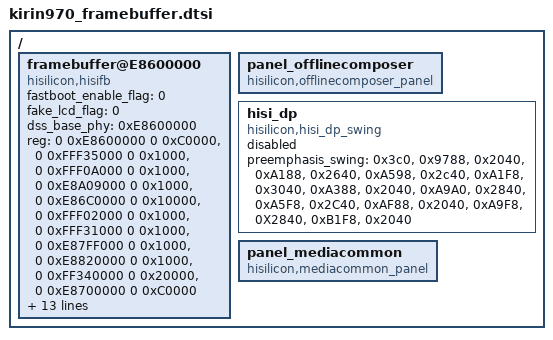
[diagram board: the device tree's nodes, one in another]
/*
 * Hisilicon Ltd. hi3xxxASIC SoC
 *
 * Copyright (C) 2013 Hisilicon Technologies CO., Ltd.
 *
 * This program is free software; you can redistribute it and/or modify
 * it under the terms of the GNU General Public License version 2 as
 * publishhed by the Free Software Foundation.
 */
/ {
	framebuffer@E8600000 {
		#address-cells = <2>;
		#size-cells = <2>;
		compatible = "hisilicon,hisifb";
		fastboot_enable_flag = <0>;
		fake_lcd_flag = <0>;
		dss_base_phy = <0xE8600000>;
		// DSS, PERI_CRG, SCTRL, PCTRL, NOC_DSS_Service_Target, MMBUF_CFG, PMCTRL, MEDIA_CRG, MEDIA_CRG_ES, DP, MDC
		reg = <0 0xE8600000 0 0xC0000>, <0 0xFFF35000 0 0x1000>, <0 0xFFF0A000 0 0x1000>, <0 0xE8A09000 0 0x1000>,
			<0 0xE86C0000 0 0x10000>, <0 0xFFF02000 0 0x1000>, <0 0xFFF31000 0 0x1000>, <0 0xE87FF000 0 0x1000>, <0 0xE8820000 0 0x1000>, <0 0xFF340000 0 0x20000>,
			<0 0xE8700000 0 0xC0000>;
		// dss-pdp, dss-sdp, dss-adp, dss-dsi0, dss-dsi1, dp, mdc_ns irq
		interrupts = <0 245 4>, <0 246 4>, <0 247 4>, <0 251 4>, <0 252 4>, <0 331 4>, <0 287 4>;
		regulator_dsssubsys-supply = <&dsssubsys>;
		regulator_mmbuf-supply = <&mmbuf>;
		regulator_media_subsys-supply = <&media_subsys>;
		clocks = <&aclk_gate_dss>, <&pclk_gate_dss>, <&clk_gate_edc0>, <&clk_gate_ldi0>, <&clk_gate_ldi1>,
			<&clk_gate_dss_axi_mm>, <&pclk_gate_mmbuf>,
			<&clk_gate_txdphy0_ref>, <&clk_gate_txdphy1_ref>, <&clk_gate_txdphy0_cfg>, <&clk_gate_txdphy1_cfg>,
			<&pclk_gate_dsi0>, <&pclk_gate_dsi1>, <&pclk_gate_pctrl>, <&clk_gate_dpctrl_16m>,
			<&pclk_gate_dpctrl>, <&aclk_gate_dpctrl>;
		clock-names = "aclk_dss", "pclk_dss", "clk_edc0", "clk_ldi0", "clk_ldi1",
			"clk_dss_axi_mm", "pclk_mmbuf",
			"clk_txdphy0_ref", "clk_txdphy1_ref", "clk_txdphy0_cfg", "clk_txdphy1_cfg",
			"pclk_dsi0", "pclk_dsi1", "pclk_pctrl", "clk_dpctrl_16m",
			"pclk_dpctrl", "aclk_dpctrl";
		status = "ok";

		/*iommu_info {
			start-addr = <0x8000>;
			size = <0xbfff8000>;
		};*/
	};

	panel_offlinecomposer {
		#address-cells = <2>;
		#size-cells = <2>;
		compatible = "hisilicon,offlinecomposer_panel";
		status = "ok";
	};

	hisi_dp {
		compatible = "hisilicon,hisi_dp_swing";
		preemphasis_swing = <0x3c0>, <0x9788>, <0x2040>, <0xA188>, <0x2640>, <0xA598>, <0x2c40>, <0xA1F8>, <0x3040>,
			<0xA388>, <0x2040>, <0xA9A0>, <0x2840>, <0xA5F8>, <0x2C40>, <0xAF88>, <0x2040>, <0xA9F8>, <0X2840>, <0xB1F8>, <0x2040>;
		status = "disabled";
	};

	panel_mediacommon {
		#address-cells = <2>;
		#size-cells = <2>;
		compatible = "hisilicon,mediacommon_panel";
		status = "ok";
	};
};

